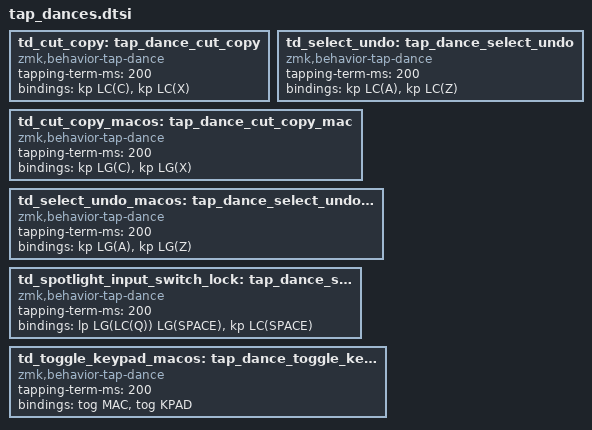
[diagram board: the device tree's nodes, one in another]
td_cut_copy: tap_dance_cut_copy {
    compatible = "zmk,behavior-tap-dance";
    #binding-cells = <0>;
    tapping-term-ms = <200>;
    bindings = <&kp LC(C)>, <&kp LC(X)>;
};

td_select_undo: tap_dance_select_undo {
    compatible = "zmk,behavior-tap-dance";
    #binding-cells = <0>;
    tapping-term-ms = <200>;
    bindings = <&kp LC(A)>, <&kp LC(Z)>;
};

td_cut_copy_macos: tap_dance_cut_copy_mac {
    compatible = "zmk,behavior-tap-dance";
    #binding-cells = <0>;
    tapping-term-ms = <200>;
    bindings = <&kp LG(C)>, <&kp LG(X)>;
};

td_select_undo_macos: tap_dance_select_undo_mac {
    compatible = "zmk,behavior-tap-dance";
    #binding-cells = <0>;
    tapping-term-ms = <200>;
    bindings = <&kp LG(A)>, <&kp LG(Z)>;
};

// Needs custom_behaviors.dtsi inclusion to work
td_spotlight_input_switch_lock: tap_dance_spotlight_input_switch {
    compatible = "zmk,behavior-tap-dance";
    #binding-cells = <0>;
    tapping-term-ms = <200>;
    bindings = <&lp LG(LC(Q)) LG(SPACE)>, <&kp LC(SPACE)>;
};

// Keep the keypad toggle for... emergencies? On double-tap
td_toggle_keypad_macos: tap_dance_toggle_keypad_macos {
    compatible = "zmk,behavior-tap-dance";
    #binding-cells = <0>;
    tapping-term-ms = <200>;
    bindings = <&tog MAC>, <&tog KPAD>;
};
